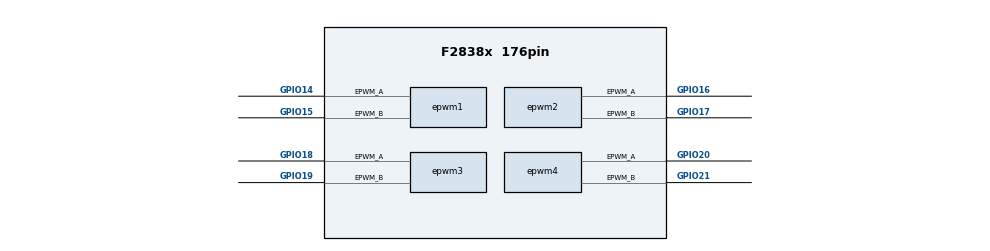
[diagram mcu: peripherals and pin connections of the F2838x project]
/**
 * @cliArgs --device "F2838x" --part "F2838x_176pin" --package "176pin" --context "CPU1" --product "C2000WARE@5.00.00.00"
 * @versions {"tool":"1.21.0+3721"}
 */

/**
 * Import the modules used in this configuration.
 */
const adc       = scripting.addModule("/driverlib/adc.js", {}, false);
const adc1      = adc.addInstance();
const adc2      = adc.addInstance();
const adc3      = adc.addInstance();
const adc4      = adc.addInstance();
const cputimer  = scripting.addModule("/driverlib/cputimer.js", {}, false);
const cputimer1 = cputimer.addInstance();
const epwm      = scripting.addModule("/driverlib/epwm.js");
const epwm1     = epwm.addInstance();
const epwm2     = epwm.addInstance();
const epwm3     = epwm.addInstance();
const epwm4     = epwm.addInstance();

/**
 * Write custom configuration values to the imported modules.
 */
adc1.adcClockPrescaler       = "ADC_CLK_DIV_4_0";
adc1.interruptPulseMode      = "ADC_PULSE_END_OF_CONV";
adc1.enabledInts             = ["ADC_INT_NUMBER1"];
adc1.enableInterrupt1        = true;
adc1.registerInterrupts      = ["1"];
adc1.adcBase                 = "ADCD_BASE";
adc1.soc0Name                = "DAB_IPRIMTANK";
adc1.soc0Trigger             = "ADC_TRIGGER_EPWM8_SOCA";
adc1.soc0SampleWindow        = 31;
adc1.$name                   = "ADCD_BASE";
adc1.soc1SampleWindow        = 31;
adc1.soc2Name                = "DAB_VSEC";
adc1.soc2Channel             = "ADC_CH_ADCIN2";
adc1.soc2Trigger             = "ADC_TRIGGER_EPWM8_SOCA";
adc1.soc2SampleWindow        = 31;
adc1.soc3Name                = "DAB_IPRIM";
adc1.soc3Trigger             = "ADC_TRIGGER_EPWM8_SOCA";
adc1.soc3SampleWindow        = 31;
adc1.soc3Channel             = "ADC_CH_ADCIN2";
adc1.soc4Name                = "DAB_VPRIM";
adc1.soc4Channel             = "ADC_CH_ADCIN3";
adc1.soc4SampleWindow        = 31;
adc1.soc4Trigger             = "ADC_TRIGGER_EPWM8_SOCA";
adc1.soc1Name                = "DAB_ISEC";
adc1.soc1Channel             = "ADC_CH_ADCIN4";
adc1.soc5Name                = "PS_1V65";
adc1.soc5Channel             = "ADC_CH_ADCIN3";
adc1.soc5Trigger             = "ADC_TRIGGER_CPU1_TINT2";
adc1.soc5SampleWindow        = 31;
adc1.enabledSOCs             = ["ADC_SOC_NUMBER0","ADC_SOC_NUMBER3","ADC_SOC_NUMBER5"];
adc1.adcInt1.enableInterrupt = true;

adc2.$name                   = "ADCA_BASE";
adc2.adcClockPrescaler       = "ADC_CLK_DIV_4_0";
adc2.soc0Name                = "ISEC_TANK";
adc2.soc0Channel             = "ADC_CH_ADCIN14";
adc2.soc0Trigger             = "ADC_TRIGGER_EPWM8_SOCA";
adc2.soc0SampleWindow        = 31;
adc2.interruptPulseMode      = "ADC_PULSE_END_OF_CONV";
adc2.enabledInts             = ["ADC_INT_NUMBER1"];
adc2.enableInterrupt1        = true;
adc2.registerInterrupts      = ["1"];
adc2.enabledSOCs             = ["ADC_SOC_NUMBER0","ADC_SOC_NUMBER1"];
adc2.soc1Name                = "DAB_ISEC";
adc2.soc1Channel             = "ADC_CH_ADCIN4";
adc2.soc1SampleWindow        = 31;
adc2.soc1Trigger             = "ADC_TRIGGER_EPWM8_SOCA";
adc2.adcInt1.enableInterrupt = true;

adc3.$name             = "ADCC_BASE";
adc3.adcBase           = "ADCC_BASE";
adc3.adcClockPrescaler = "ADC_CLK_DIV_4_0";
adc3.enabledSOCs       = ["ADC_SOC_NUMBER0"];
adc3.soc0Name          = "DAB_VSEC";
adc3.soc0Channel       = "ADC_CH_ADCIN2";
adc3.soc0SampleWindow  = 31;
adc3.soc0Trigger       = "ADC_TRIGGER_EPWM8_SOCA";

adc4.$name             = "ADCB_BASE";
adc4.adcBase           = "ADCB_BASE";
adc4.adcClockPrescaler = "ADC_CLK_DIV_4_0";
adc4.enabledSOCs       = ["ADC_SOC_NUMBER0"];
adc4.soc0Name          = "DAB_VPRIM";
adc4.soc0Channel       = "ADC_CH_ADCIN3";
adc4.soc0SampleWindow  = 31;
adc4.soc0Trigger       = "ADC_TRIGGER_EPWM8_SOCA";

cputimer1.emulationMode            = "CPUTIMER_EMULATIONMODE_STOPATZERO";
cputimer1.enableInterrupt          = true;
cputimer1.registerInterrupts       = true;
cputimer1.startTimer               = true;
cputimer1.timerPeriod              = 1999;
cputimer1.cputimerBase             = "CPUTIMER2_BASE";
cputimer1.$name                    = "myCPUTIMER2";
cputimer1.timerInt.enableInterrupt = true;

epwm1.$name                                                      = "myEPWM0";
epwm1.epwmGlobalLoad_gld                                         = true;
epwm1.epwmGlobalLoad_enableOneShot                               = true;
epwm1.epwmGlobalLoad_oneShotMode                                 = true;
epwm1.epwmTimebase_hsClockDiv                                    = "EPWM_HSCLOCK_DIVIDER_1";
epwm1.epwmTimebase_period                                        = 500;
epwm1.epwmTimebase_periodGld                                     = true;
epwm1.epwmTimebase_counterMode                                   = "EPWM_COUNTER_MODE_UP_DOWN";
epwm1.epwmTimebase_syncInPulseSource                             = "EPWM_SYNC_IN_PULSE_SRC_DISABLE";
epwm1.epwmTimebase_syncOutPulseMode                              = ["EPWM_SYNC_OUT_PULSE_ON_CNTR_ZERO"];
epwm1.epwmCounterCompare_cmpA                                    = 250;
epwm1.epwmCounterCompare_cmpAGld                                 = true;
epwm1.epwmDeadband_enableRED                                     = true;
epwm1.epwmDeadband_enableFED                                     = true;
epwm1.epwmEventTrigger_EPWM_SOC_A_triggerEnable                  = true;
epwm1.epwmEventTrigger_EPWM_SOC_A_triggerSource                  = "EPWM_SOC_TBCTR_U_CMPA";
epwm1.epwmEventTrigger_EPWM_SOC_B_triggerEnable                  = true;
epwm1.epwmEventTrigger_EPWM_SOC_B_triggerSource                  = "EPWM_SOC_TBCTR_D_CMPA";
epwm1.epwmEventTrigger_EPWM_SOC_A_triggerEventPrescalar          = "1";
epwm1.epwmEventTrigger_EPWM_SOC_B_triggerEventPrescalar          = "1";
epwm1.epwmDeadband_delayRED                                      = 16380;
epwm1.epwmDeadband_delayFED                                      = 16380;
epwm1.epwmActionQualifier_EPWM_AQ_OUTPUT_A_ON_TIMEBASE_UP_CMPA   = "EPWM_AQ_OUTPUT_HIGH";
epwm1.epwmActionQualifier_EPWM_AQ_OUTPUT_A_ON_TIMEBASE_DOWN_CMPA = "EPWM_AQ_OUTPUT_LOW";
epwm1.epwmActionQualifier_EPWM_AQ_OUTPUT_B_gld                   = true;
epwm1.epwmActionQualifier_EPWM_AQ_OUTPUT_B_shadowMode            = true;
epwm1.epwmDeadband_polarityFED                                   = "EPWM_DB_POLARITY_ACTIVE_LOW";
epwm1.epwm.$assign                                               = "EPWM8";
epwm1.epwm.epwm_aPin.$assign                                     = "GPIO14";
epwm1.epwm.epwm_bPin.$assign                                     = "GPIO15";

epwm2.epwmGlobalLoad_gld                                         = true;
epwm2.epwmGlobalLoad_enableOneShot                               = true;
epwm2.epwmGlobalLoad_oneShotMode                                 = true;
epwm2.epwmTimebase_hsClockDiv                                    = "EPWM_HSCLOCK_DIVIDER_1";
epwm2.epwmTimebase_period                                        = 500;
epwm2.epwmTimebase_counterMode                                   = "EPWM_COUNTER_MODE_UP_DOWN";
epwm2.epwmTimebase_counterModeAfterSync                          = "EPWM_COUNT_MODE_UP_AFTER_SYNC";
epwm2.epwmCounterCompare_cmpA                                    = 250;
epwm2.epwmDeadband_enableRED                                     = true;
epwm2.epwmDeadband_delayRED                                      = 16380;
epwm2.epwmDeadband_polarityFED                                   = "EPWM_DB_POLARITY_ACTIVE_LOW";
epwm2.epwmDeadband_enableFED                                     = true;
epwm2.epwmDeadband_delayFED                                      = 16380;
epwm2.$name                                                      = "DAB_PRIM2";
epwm2.epwmGlobalLoad_gldMode                                     = "EPWM_GL_LOAD_PULSE_SYNC";
epwm2.epwmGlobalLoad_globalePWMLoadLink                          = "EPWM_LINK_WITH_EPWM_8";
epwm2.epwmTimebase_periodLink                                    = "EPWM_LINK_WITH_EPWM_8";
epwm2.epwmTimebase_phaseEnable                                   = true;
epwm2.epwmTimebase_phaseShift                                    = 2;
epwm2.epwmTimebase_syncInPulseSource                             = "EPWM_SYNC_IN_PULSE_SRC_SYNCOUT_EPWM8";
epwm2.epwmCounterCompare_cmpALink                                = "EPWM_LINK_WITH_EPWM_8";
epwm2.epwmActionQualifier_EPWM_AQ_OUTPUT_A_shadowMode            = true;
epwm2.epwmActionQualifier_EPWM_AQ_OUTPUT_B_shadowMode            = true;
epwm2.epwmActionQualifier_EPWM_AQ_OUTPUT_B_gld                   = true;
epwm2.epwmActionQualifier_EPWM_AQ_OUTPUT_B_shadowEvent           = "EPWM_AQ_LOAD_ON_SYNC_ONLY";
epwm2.epwmCounterCompare_shadowLoadModeCMPA                      = "EPWM_COMP_LOAD_ON_SYNC_ONLY";
epwm2.epwmCounterCompare_shadowLoadModeCMPB                      = "EPWM_COMP_LOAD_ON_SYNC_ONLY";
epwm2.epwmActionQualifier_EPWM_AQ_OUTPUT_A_ON_TIMEBASE_ZERO      = "EPWM_AQ_OUTPUT_HIGH";
epwm2.epwmActionQualifier_EPWM_AQ_OUTPUT_A_ON_TIMEBASE_PERIOD    = "EPWM_AQ_OUTPUT_LOW";
epwm2.epwmActionQualifier_EPWM_AQ_OUTPUT_A_ON_TIMEBASE_UP_CMPA   = "EPWM_AQ_OUTPUT_LOW";
epwm2.epwmActionQualifier_EPWM_AQ_OUTPUT_A_ON_TIMEBASE_DOWN_CMPA = "EPWM_AQ_OUTPUT_HIGH";
epwm2.epwm.epwm_aPin.$assign                                     = "GPIO16";
epwm2.epwm.epwm_bPin.$assign                                     = "GPIO17";
scripting.suppress("It is recommended to use a non-zero counter compare value when using shadow to active load of action qualifier A/B control register on TBCTR=0 boundary", epwm2, "epwmCounterCompare_cmpB");
scripting.suppress("It is recommended to use a non-zero counter compare value when using shadow to active load of action qualifier A/B control register on TBCTR=0 boundary", epwm2, "epwmCounterCompare_cmpA");

epwm3.$name                                                      = "DAB_SEC1";
epwm3.copyUse                                                    = true;
epwm3.copyFrom                                                   = "DAB_PRIM2";
epwm3.epwmGlobalLoad_gld                                         = true;
epwm3.epwmGlobalLoad_gldMode                                     = "EPWM_GL_LOAD_PULSE_SYNC";
epwm3.epwmGlobalLoad_enableOneShot                               = true;
epwm3.epwmGlobalLoad_oneShotMode                                 = true;
epwm3.epwmGlobalLoad_globalePWMLoadLink                          = "EPWM_LINK_WITH_EPWM_8";
epwm3.epwmTimebase_hsClockDiv                                    = "EPWM_HSCLOCK_DIVIDER_1";
epwm3.epwmTimebase_period                                        = 500;
epwm3.epwmTimebase_periodLink                                    = "EPWM_LINK_WITH_EPWM_8";
epwm3.epwmTimebase_counterMode                                   = "EPWM_COUNTER_MODE_UP_DOWN";
epwm3.epwmTimebase_phaseEnable                                   = true;
epwm3.epwmTimebase_counterModeAfterSync                          = "EPWM_COUNT_MODE_UP_AFTER_SYNC";
epwm3.epwmTimebase_phaseShift                                    = 2;
epwm3.epwmTimebase_syncInPulseSource                             = "EPWM_SYNC_IN_PULSE_SRC_SYNCOUT_EPWM8";
epwm3.epwmCounterCompare_cmpA                                    = 250;
epwm3.epwmCounterCompare_cmpALink                                = "EPWM_LINK_WITH_EPWM_8";
epwm3.epwmActionQualifier_EPWM_AQ_OUTPUT_A_shadowMode            = true;
epwm3.epwmActionQualifier_EPWM_AQ_OUTPUT_A_shadowEvent           = "EPWM_AQ_LOAD_ON_SYNC_ONLY";
epwm3.epwmActionQualifier_EPWM_AQ_OUTPUT_A_ON_TIMEBASE_ZERO      = "EPWM_AQ_OUTPUT_LOW";
epwm3.epwmActionQualifier_EPWM_AQ_OUTPUT_A_ON_TIMEBASE_PERIOD    = "EPWM_AQ_OUTPUT_HIGH";
epwm3.epwmActionQualifier_EPWM_AQ_OUTPUT_A_ON_TIMEBASE_UP_CMPA   = "EPWM_AQ_OUTPUT_HIGH";
epwm3.epwmActionQualifier_EPWM_AQ_OUTPUT_A_ON_TIMEBASE_DOWN_CMPA = "EPWM_AQ_OUTPUT_LOW";
epwm3.epwmActionQualifier_EPWM_AQ_OUTPUT_B_gld                   = true;
epwm3.epwmActionQualifier_EPWM_AQ_OUTPUT_B_shadowMode            = true;
epwm3.epwmActionQualifier_EPWM_AQ_OUTPUT_B_shadowEvent           = "EPWM_AQ_LOAD_ON_SYNC_ONLY";
epwm3.epwmDeadband_polarityFED                                   = "EPWM_DB_POLARITY_ACTIVE_LOW";
epwm3.epwmDeadband_enableRED                                     = true;
epwm3.epwmDeadband_delayRED                                      = 16380;
epwm3.epwmDeadband_delayFED                                      = 16380;
epwm3.epwmDeadband_enableFED                                     = true;
epwm3.epwmDeadband_controlShadowMode                             = true;
epwm3.epwmDeadband_redShadowMode                                 = true;
epwm3.epwmDeadband_fedShadowMode                                 = true;
epwm3.epwm.$assign                                               = "EPWM10";
epwm3.epwm.epwm_aPin.$assign                                     = "GPIO18";
epwm3.epwm.epwm_bPin.$assign                                     = "GPIO19";

epwm4.$name                                                      = "DAB_SEC2";
epwm4.epwmGlobalLoad_gld                                         = true;
epwm4.epwmGlobalLoad_gldMode                                     = "EPWM_GL_LOAD_PULSE_SYNC";
epwm4.epwmGlobalLoad_enableOneShot                               = true;
epwm4.epwmGlobalLoad_oneShotMode                                 = true;
epwm4.epwmGlobalLoad_globalePWMLoadLink                          = "EPWM_LINK_WITH_EPWM_8";
epwm4.epwmTimebase_hsClockDiv                                    = "EPWM_HSCLOCK_DIVIDER_1";
epwm4.epwmTimebase_period                                        = 500;
epwm4.epwmTimebase_counterMode                                   = "EPWM_COUNTER_MODE_UP_DOWN";
epwm4.epwmTimebase_counterModeAfterSync                          = "EPWM_COUNT_MODE_UP_AFTER_SYNC";
epwm4.epwmTimebase_phaseEnable                                   = true;
epwm4.epwmTimebase_phaseShift                                    = 2;
epwm4.epwmTimebase_syncInPulseSource                             = "EPWM_SYNC_IN_PULSE_SRC_SYNCOUT_EPWM8";
epwm4.epwmCounterCompare_cmpA                                    = 250;
epwm4.epwmCounterCompare_cmpALink                                = "EPWM_LINK_WITH_EPWM_8";
epwm4.epwmCounterCompare_shadowLoadModeCMPA                      = "EPWM_COMP_LOAD_ON_SYNC_ONLY";
epwm4.epwmCounterCompare_shadowLoadModeCMPB                      = "EPWM_COMP_LOAD_ON_SYNC_ONLY";
epwm4.epwmActionQualifier_EPWM_AQ_OUTPUT_A_shadowMode            = true;
epwm4.epwmActionQualifier_EPWM_AQ_OUTPUT_A_shadowEvent           = "EPWM_AQ_LOAD_ON_SYNC_ONLY";
epwm4.epwmActionQualifier_EPWM_AQ_OUTPUT_A_ON_TIMEBASE_ZERO      = "EPWM_AQ_OUTPUT_HIGH";
epwm4.epwmActionQualifier_EPWM_AQ_OUTPUT_A_ON_TIMEBASE_PERIOD    = "EPWM_AQ_OUTPUT_LOW";
epwm4.epwmActionQualifier_EPWM_AQ_OUTPUT_A_ON_TIMEBASE_UP_CMPA   = "EPWM_AQ_OUTPUT_LOW";
epwm4.epwmActionQualifier_EPWM_AQ_OUTPUT_A_ON_TIMEBASE_DOWN_CMPA = "EPWM_AQ_OUTPUT_HIGH";
epwm4.epwmActionQualifier_EPWM_AQ_OUTPUT_B_gld                   = true;
epwm4.epwmActionQualifier_EPWM_AQ_OUTPUT_B_shadowMode            = true;
epwm4.epwmDeadband_polarityFED                                   = "EPWM_DB_POLARITY_ACTIVE_LOW";
epwm4.epwmDeadband_enableRED                                     = true;
epwm4.epwmDeadband_delayRED                                      = 16380;
epwm4.epwmDeadband_delayFED                                      = 16380;
epwm4.epwmDeadband_enableFED                                     = true;
epwm4.epwmDeadband_redShadowMode                                 = true;
epwm4.epwmDeadband_fedShadowMode                                 = true;
epwm4.epwm.$assign                                               = "EPWM11";
epwm4.epwm.epwm_aPin.$assign                                     = "GPIO20";
epwm4.epwm.epwm_bPin.$assign                                     = "GPIO21";
scripting.suppress("It is recommended to use a non-zero counter compare value when using shadow to active load of action qualifier A/B control register on TBCTR=0 boundary", epwm4, "epwmCounterCompare_cmpB");
scripting.suppress("It is recommended to use a non-zero counter compare value when using shadow to active load of action qualifier A/B control register on TBCTR=0 boundary", epwm4, "epwmCounterCompare_cmpA");

/**
 * Pinmux solution for unlocked pins/peripherals. This ensures that minor changes to the automatic solver in a future
 * version of the tool will not impact the pinmux you originally saw.  These lines can be completely deleted in order to
 * re-solve from scratch.
 */
epwm2.epwm.$suggestSolution = "EPWM9";
